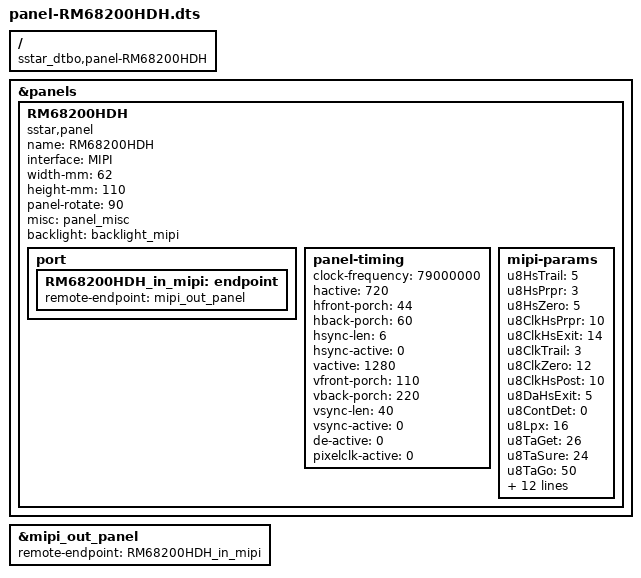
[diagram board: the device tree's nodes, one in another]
/dts-v1/;
/plugin/;

/ {
    compatible = "sstar_dtbo,panel-RM68200HDH";
};

&panels {
    RM68200HDH {
        compatible = "sstar,panel";
        name = "RM68200HDH";
        interface = "MIPI"; /* TTL/MIPI/LVDS/BT1120/BT656 */
        width-mm = <62>;
        height-mm = <110>;
        panel-rotate = <90>;
        misc = <&panel_misc>;
        backlight = <&backlight_mipi>;
        status = "okay";

        port {
            RM68200HDH_in_mipi: endpoint {
                remote-endpoint = <&mipi_out_panel>;
            };
        };

        panel-timing {
            clock-frequency = <79000000>;
            hactive = <720>;
            hfront-porch = <44>;
            hback-porch = <60>;
            hsync-len = <6>;
            hsync-active = <0>;
            vactive = <1280>;
            vfront-porch = <110>;
            vback-porch = <220>;
            vsync-len = <40>;
            vsync-active = <0>;
            de-active = <0>;
            pixelclk-active = <0>;
        };

        mipi-params {
            u8HsTrail = <5>; /* HsTrail */
            u8HsPrpr = <3>; /* HsPrpr */
            u8HsZero = <5>; /* HsZero */
            u8ClkHsPrpr = <10>; /* ClkHsPrpr */
            u8ClkHsExit = <14>; /* ClkHsexit */
            u8ClkTrail = <3>; /* ClkTrail */
            u8ClkZero = <12>; /* ClkZero */
            u8ClkHsPost = <10>; /* ClkHsPost */
            u8DaHsExit = <5>; /* DaHsexit */
            u8ContDet = <0>; /* ConDet */
            u8Lpx = <16>; /* Lpx */
            u8TaGet = <26>; /* TaGet */
            u8TaSure = <24>; /* TaSure */
            u8TaGo = <50>; /* TaGo */

            u16Bllp = <0>; /* Bllp */
            u16Fps = <60>; /* Frame Rate */

            enFormat = <3>; /* Output color format, 0:rgb565, 1:rgb666, 2:loosely rgb666, 3:rgb888 */
            enCtrl = <1>; /* cotnrol mode, 0:cmd mode, 1:sync pluse, 2:sync event, 3:burst mode */

            u8SyncCalibrate = <0>;
            u16VirHsyncSt = <0>;
            u16VirHsyncEnd = <0>;
            u16VsyncRef = <0>;
            u16DataClkSkew = <7>;

            enPacketType = <0>; /* Mipidsi command type, 0:DCS mode, 1:generic mode */
            mipi-init-cmds = /bits/ 8 <
                0xFE 0x01 0x01
                0x24 0x01 0xC0
                0x25 0x01 0x53
                0x26 0x01 0x00
                0x27 0x01 0x0A
                0x29 0x01 0x0A
                0x2B 0x01 0xE5
                0x2F 0x01 0x44
                0x34 0x01 0x55
                0x1B 0x01 0x00
                0x12 0x01 0x08
                0x46 0x01 0xA4
                0x52 0x01 0xA8
                0x53 0x01 0x00
                0x54 0x01 0xA8
                0x55 0x01 0x00
                0xFE 0x01 0x03
                0x00 0x01 0x05
                0x01 0x01 0x14
                0x02 0x01 0x01
                0x03 0x01 0x00
                0x04 0x01 0x00
                0x05 0x01 0x00
                0x06 0x01 0x00
                0x07 0x01 0x00
                0x08 0x01 0x00
                0x09 0x01 0x00
                0x0A 0x01 0x00
                0x0B 0x01 0x00
                0x0C 0x01 0x00
                0x0D 0x01 0x00
                0x0E 0x01 0x05
                0x0F 0x01 0x06
                0x10 0x01 0x07
                0x11 0x01 0x08
                0x12 0x01 0x00
                0x13 0x01 0x40
                0x14 0x01 0x00
                0x15 0x01 0xC5
                0x16 0x01 0x08
                0x17 0x01 0x09
                0x18 0x01 0x0A
                0x19 0x01 0x0B
                0x1A 0x01 0x0C
                0x1B 0x01 0x00
                0x1C 0x01 0x40
                0x1D 0x01 0x00
                0x1E 0x01 0x85
                0x1F 0x01 0x08
                0x20 0x01 0x00
                0x21 0x01 0x00
                0x22 0x01 0x05
                0x23 0x01 0x0C
                0x24 0x01 0x00
                0x25 0x01 0x28
                0x26 0x01 0x00
                0x27 0x01 0x10
                0x28 0x01 0x00
                0x29 0x01 0x28
                0x2A 0x01 0x00
                0x2B 0x01 0x00
                0x2D 0x01 0x00
                0x2F 0x01 0x00
                0x30 0x01 0x00
                0x31 0x01 0x00
                0x32 0x01 0x00
                0x33 0x01 0x00
                0x34 0x01 0x00
                0x35 0x01 0x00
                0x36 0x01 0x00
                0x37 0x01 0x00
                0x38 0x01 0x00
                0x39 0x01 0x00
                0x3A 0x01 0x00
                0x3B 0x01 0x00
                0x3D 0x01 0x00
                0x3F 0x01 0x00
                0x40 0x01 0x00
                0x41 0x01 0x00
                0x42 0x01 0x00
                0x43 0x01 0x00
                0x44 0x01 0x00
                0x45 0x01 0x00
                0x46 0x01 0x00
                0x47 0x01 0x00
                0x48 0x01 0x00
                0x49 0x01 0x00
                0x4A 0x01 0x00
                0x4B 0x01 0x00
                0x4C 0x01 0x00
                0x4D 0x01 0x00
                0x4E 0x01 0x00
                0x4F 0x01 0x00
                0x50 0x01 0x00
                0x51 0x01 0x00
                0x52 0x01 0x00
                0x53 0x01 0x00
                0x54 0x01 0x00
                0x55 0x01 0x00
                0x56 0x01 0x00
                0x58 0x01 0x00
                0x59 0x01 0x00
                0x5A 0x01 0x00
                0x5B 0x01 0x00
                0x5C 0x01 0x00
                0x5D 0x01 0x00
                0x5E 0x01 0x00
                0x5F 0x01 0x00
                0x60 0x01 0x00
                0x61 0x01 0x00
                0x62 0x01 0x00
                0x63 0x01 0x00
                0x64 0x01 0x00
                0x65 0x01 0x00
                0x66 0x01 0x00
                0x67 0x01 0x00
                0x68 0x01 0x00
                0x69 0x01 0x00
                0x6A 0x01 0x00
                0x6B 0x01 0x00
                0x6C 0x01 0x00
                0x6D 0x01 0xBC
                0x6E 0x01 0x20
                0x6F 0x01 0x00
                0x70 0x01 0x00
                0x71 0x01 0x88
                0x72 0x01 0x00
                0x73 0x01 0x00
                0x74 0x01 0x01
                0x75 0x01 0x01
                0x76 0x01 0x01
                0x77 0x01 0x01
                0x78 0x01 0x00
                0x79 0x01 0x00
                0x7A 0x01 0x00
                0x7B 0x01 0x00
                0x7C 0x01 0x00
                0x7D 0x01 0x00
                0x7E 0x01 0x1D
                0x7F 0x01 0x1C
                0x80 0x01 0x1A
                0x81 0x01 0x1B
                0x82 0x01 0x0D
                0x83 0x01 0x0F
                0x84 0x01 0x09
                0x85 0x01 0x0B
                0x86 0x01 0x01
                0x87 0x01 0x3F
                0x88 0x01 0x03
                0x89 0x01 0x1C
                0x8A 0x01 0x3F
                0x8B 0x01 0x1C
                0x8C 0x01 0x1C
                0x8D 0x01 0x3F
                0x8E 0x01 0x3F
                0x8F 0x01 0x3F
                0x90 0x01 0x3F
                0x91 0x01 0x3F
                0x92 0x01 0x3F
                0x93 0x01 0x3F
                0x94 0x01 0x3F
                0x95 0x01 0x3F
                0x96 0x01 0x3F
                0x97 0x01 0x3F
                0x98 0x01 0x3F
                0x99 0x01 0x3F
                0x9A 0x01 0x3F
                0x9B 0x01 0x1C
                0x9C 0x01 0x1C
                0x9D 0x01 0x3F
                0x9E 0x01 0x1C
                0x9F 0x01 0x02
                0xA0 0x01 0x3F
                0xA2 0x01 0x00
                0xA3 0x01 0x0A
                0xA4 0x01 0x08
                0xA5 0x01 0x0E
                0xA6 0x01 0x0C
                0xA7 0x01 0x19
                0xA9 0x01 0x18
                0xAA 0x01 0x1C
                0xAB 0x01 0x1D
                0xAC 0x01 0x1C
                0xAD 0x01 0x1D
                0xAE 0x01 0x1A
                0xAF 0x01 0x1B
                0xB0 0x01 0x0A
                0xB1 0x01 0x08
                0xB2 0x01 0x0E
                0xB3 0x01 0x0C
                0xB4 0x01 0x02
                0xB5 0x01 0x3F
                0xB6 0x01 0x00
                0xB7 0x01 0x1C
                0xB8 0x01 0x3F
                0xB9 0x01 0x1C
                0xBA 0x01 0x1C
                0xBB 0x01 0x3F
                0xBC 0x01 0x3F
                0xBD 0x01 0x3F
                0xBE 0x01 0x3F
                0xBF 0x01 0x3F
                0xC0 0x01 0x3F
                0xC1 0x01 0x3F
                0xC2 0x01 0x3F
                0xC3 0x01 0x3F
                0xC4 0x01 0x3F
                0xC5 0x01 0x3F
                0xC6 0x01 0x3F
                0xC7 0x01 0x3F
                0xC8 0x01 0x3F
                0xC9 0x01 0x1C
                0xCA 0x01 0x1C
                0xCB 0x01 0x3F
                0xCC 0x01 0x1C
                0xCD 0x01 0x01
                0xCE 0x01 0x3F
                0xCF 0x01 0x03
                0xD0 0x01 0x0D
                0xD1 0x01 0x0F
                0xD2 0x01 0x09
                0xD3 0x01 0x0B
                0xD4 0x01 0x19
                0xD5 0x01 0x18
                0xD6 0x01 0x1D
                0xD7 0x01 0x1C
                0xDC 0x01 0x02
                0xDE 0x01 0x0C
                0xDF 0x01 0x00
                0xFE 0x01 0x0E
                0x01 0x01 0x75
                0x54 0x01 0x01
                0xFE 0x01 0x04
                0x60 0x01 0x00
                0x61 0x01 0x0A
                0x62 0x01 0x10
                0x63 0x01 0x0D
                0x64 0x01 0x06
                0x65 0x01 0x12
                0x66 0x01 0x0F
                0x67 0x01 0x0B
                0x68 0x01 0x16
                0x69 0x01 0x0C
                0x6A 0x01 0x0F
                0x6B 0x01 0x08
                0x6C 0x01 0x11
                0x6D 0x01 0x17
                0x6E 0x01 0x12
                0x6F 0x01 0x00
                0x70 0x01 0x00
                0x71 0x01 0x0A
                0x72 0x01 0x10
                0x73 0x01 0x0D
                0x74 0x01 0x06
                0x75 0x01 0x12
                0x76 0x01 0x0F
                0x77 0x01 0x0B
                0x78 0x01 0x16
                0x79 0x01 0x0C
                0x7A 0x01 0x0F
                0x7B 0x01 0x08
                0x7C 0x01 0x11
                0x7D 0x01 0x17
                0x7E 0x01 0x12
                0x7F 0x01 0x00
                0xFE 0x01 0x00
                0x58 0x01 0xAD
                0x11 0x01 0x00
                0xFE 0xFE 0xC8
                0x29 0x01 0x00
                0xFE 0xFE 0x32
            >;
        };
    };
};

&mipi_out_panel {
    remote-endpoint = <&RM68200HDH_in_mipi>;
};

